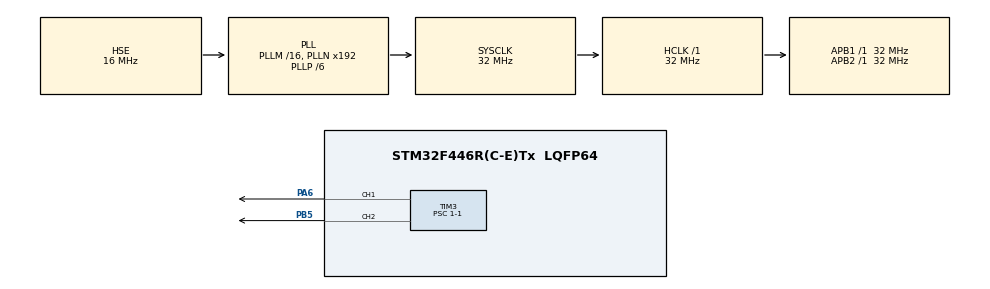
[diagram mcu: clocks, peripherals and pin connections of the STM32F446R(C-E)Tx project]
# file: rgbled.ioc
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Dma.Request0=TIM3_CH2
Dma.Request1=TIM3_CH1/TRIG
Dma.TIM3_CH1/TRIG.1.Direction=DMA_MEMORY_TO_PERIPH
Dma.TIM3_CH1/TRIG.1.FIFOMode=DMA_FIFOMODE_DISABLE
Dma.TIM3_CH1/TRIG.1.Instance=DMA1_Stream4
Dma.TIM3_CH1/TRIG.1.MemDataAlignment=DMA_MDATAALIGN_WORD
Dma.TIM3_CH1/TRIG.1.MemInc=DMA_MINC_ENABLE
Dma.TIM3_CH1/TRIG.1.Mode=DMA_CIRCULAR
Dma.TIM3_CH1/TRIG.1.PeriphDataAlignment=DMA_PDATAALIGN_WORD
Dma.TIM3_CH1/TRIG.1.PeriphInc=DMA_PINC_DISABLE
Dma.TIM3_CH1/TRIG.1.Priority=DMA_PRIORITY_VERY_HIGH
Dma.TIM3_CH2.0.Direction=DMA_MEMORY_TO_PERIPH
Dma.TIM3_CH2.0.FIFOMode=DMA_FIFOMODE_DISABLE
Dma.TIM3_CH2.0.Instance=DMA1_Stream5
Dma.TIM3_CH2.0.MemDataAlignment=DMA_MDATAALIGN_WORD
Dma.TIM3_CH2.0.MemInc=DMA_MINC_ENABLE
Dma.TIM3_CH2.0.Mode=DMA_CIRCULAR
Dma.TIM3_CH2.0.PeriphDataAlignment=DMA_PDATAALIGN_WORD
Dma.TIM3_CH2.0.PeriphInc=DMA_PINC_DISABLE
Dma.TIM3_CH2.0.Priority=DMA_PRIORITY_VERY_HIGH
Mcu.Family=STM32F4
Mcu.Name=STM32F446R(C-E)Tx
Mcu.Package=LQFP64
NVIC.DMA1_Stream4_IRQn=true\:0\:0\:false\:false\:true\:false\:true\:true
NVIC.DMA1_Stream5_IRQn=true\:0\:0\:false\:false\:true\:false\:true\:true
NVIC.PriorityGroup=NVIC_PRIORITYGROUP_4
PA6.Signal=S_TIM3_CH1
PB5.Signal=S_TIM3_CH2
PH0-OSC_IN.Mode=HSE-External-Oscillator
PH0-OSC_IN.Signal=RCC_OSC_IN
PH1-OSC_OUT.Mode=HSE-External-Oscillator
PH1-OSC_OUT.Signal=RCC_OSC_OUT
ProjectManager.HeapSize=0x200
ProjectManager.StackSize=0x400
ProjectManager.TargetToolchain=STM32CubeIDE
RCC.AHBFreq_Value=32000000
RCC.APB1Freq_Value=32000000
RCC.APB1TimFreq_Value=32000000
RCC.APB2Freq_Value=32000000
RCC.APB2TimFreq_Value=32000000
RCC.CortexFreq_Value=32000000
RCC.HCLKFreq_Value=32000000
RCC.HSE_VALUE=16000000
RCC.PLLP=RCC_PLLP_DIV6
RCC.PLLSourceVirtual=RCC_PLLSOURCE_HSE
RCC.SYSCLKFreq_VALUE=32000000
RCC.SYSCLKSource=RCC_SYSCLKSOURCE_PLLCLK
RCC.USBFreq_Value=96000000
RCC.VCOOutputFreq_Value=192000000
SH.S_TIM3_CH1.0=TIM3_CH1,PWM Generation1 CH1
SH.S_TIM3_CH2.0=TIM3_CH2,PWM Generation2 CH2
TIM3.Channel-PWM\ Generation1\ CH1=TIM_CHANNEL_1
TIM3.Channel-PWM\ Generation2\ CH2=TIM_CHANNEL_2
TIM3.OCFastMode_PWM-PWM\ Generation2\ CH2=TIM_OCFAST_ENABLE
TIM3.Period=40-1
TIM3.Prescaler=1-1
VP_TIM3_VS_ClockSourceINT.Mode=Internal
board=custom

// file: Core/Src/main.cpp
/* USER CODE BEGIN Header */
/**
  ******************************************************************************
  * @file           : main.c
  * @brief          : Main program body
  ******************************************************************************
  * @attention
  *
  * Copyright (c) 2024 STMicroelectronics.
  * All rights reserved.
  *
  * This software is licensed under terms that can be found in the LICENSE file
  * in the root directory of this software component.
  * If no LICENSE file comes with this software, it is provided AS-IS.
  *
  ******************************************************************************
  */
/* USER CODE END Header */
#include "main.h"

/* USER CODE BEGIN Includes */
#include "ws2812c.h"
#include "calc.h"

/* USER CODE END Includes */

TIM_HandleTypeDef htim3;
DMA_HandleTypeDef hdma_tim3_ch2;
DMA_HandleTypeDef hdma_tim3_ch1_trig;

/* USER CODE BEGIN PV */
WS2812C NeopixelBoard(&htim3, TIM_CHANNEL_2, &hdma_tim3_ch2);
WS2812C NeopixelTape(&htim3, TIM_CHANNEL_1, &hdma_tim3_ch1_trig);
CALC calc;

uint32_t m = 0;

/* USER CODE END PV */

void SystemClock_Config(void);
static void MX_GPIO_Init(void);
static void MX_DMA_Init(void);
static void MX_TIM3_Init(void);

/* USER CODE BEGIN 0 */
void HAL_TIM_PWM_PulseFinishedCallback(TIM_HandleTypeDef *htim){
	   NeopixelBoard.execute();
	   NeopixelTape.execute();
}

/* USER CODE END 0 */

int main(void)
{

  /* MCU Configuration--------------------------------------------------------*/

  /* Reset of all peripherals, Initializes the Flash interface and the Systick. */
  HAL_Init();

  /* Configure the system clock */
  SystemClock_Config();

  /* Initialize all configured peripherals */
  MX_GPIO_Init();
  MX_DMA_Init();
  MX_TIM3_Init();
  /* USER CODE BEGIN 2 */
  NeopixelBoard.init();
  NeopixelTape.init();

  /* USER CODE END 2 */

  /* Infinite loop */
  while (1)
  {

    /* USER CODE BEGIN 3 */
	  static uint16_t i = 0;
	  i++;
	  if(i >= 360){
		  i -= 360;
	  }
		  for(uint8_t led = 0; led < 32; led++){
			  NeopixelBoard.set_hsv(led, calc.similarityPeak(led, i, 180, i * 2 / 3, 50), 255, calc.range(led, i, 180) * 10);
		  }
		  NeopixelBoard.show();
	  m++;

  }
  /* USER CODE END 3 */
}

void SystemClock_Config(void)
{
  RCC_OscInitTypeDef RCC_OscInitStruct = {0};
  RCC_ClkInitTypeDef RCC_ClkInitStruct = {0};

  /** Configure the main internal regulator output voltage
  */
  __HAL_RCC_PWR_CLK_ENABLE();
  __HAL_PWR_VOLTAGESCALING_CONFIG(PWR_REGULATOR_VOLTAGE_SCALE3);

  /** Initializes the RCC Oscillators according to the specified parameters
  * in the RCC_OscInitTypeDef structure.
  */
  RCC_OscInitStruct.OscillatorType = RCC_OSCILLATORTYPE_HSE;
  RCC_OscInitStruct.HSEState = RCC_HSE_ON;
  RCC_OscInitStruct.PLL.PLLState = RCC_PLL_ON;
  RCC_OscInitStruct.PLL.PLLSource = RCC_PLLSOURCE_HSE;
  RCC_OscInitStruct.PLL.PLLM = 16;
  RCC_OscInitStruct.PLL.PLLN = 192;
  RCC_OscInitStruct.PLL.PLLP = RCC_PLLP_DIV6;
  RCC_OscInitStruct.PLL.PLLQ = 2;
  RCC_OscInitStruct.PLL.PLLR = 2;
  if (HAL_RCC_OscConfig(&RCC_OscInitStruct) != HAL_OK)
  {
    Error_Handler();
  }

  /** Initializes the CPU, AHB and APB buses clocks
  */
  RCC_ClkInitStruct.ClockType = RCC_CLOCKTYPE_HCLK|RCC_CLOCKTYPE_SYSCLK
                              |RCC_CLOCKTYPE_PCLK1|RCC_CLOCKTYPE_PCLK2;
  RCC_ClkInitStruct.SYSCLKSource = RCC_SYSCLKSOURCE_PLLCLK;
  RCC_ClkInitStruct.AHBCLKDivider = RCC_SYSCLK_DIV1;
  RCC_ClkInitStruct.APB1CLKDivider = RCC_HCLK_DIV1;
  RCC_ClkInitStruct.APB2CLKDivider = RCC_HCLK_DIV1;

  if (HAL_RCC_ClockConfig(&RCC_ClkInitStruct, FLASH_LATENCY_1) != HAL_OK)
  {
    Error_Handler();
  }
}

static void MX_TIM3_Init(void)
{

  TIM_ClockConfigTypeDef sClockSourceConfig = {0};
  TIM_MasterConfigTypeDef sMasterConfig = {0};
  TIM_OC_InitTypeDef sConfigOC = {0};

  htim3.Instance = TIM3;
  htim3.Init.Prescaler = 1-1;
  htim3.Init.CounterMode = TIM_COUNTERMODE_UP;
  htim3.Init.Period = 40-1;
  htim3.Init.ClockDivision = TIM_CLOCKDIVISION_DIV1;
  htim3.Init.AutoReloadPreload = TIM_AUTORELOAD_PRELOAD_DISABLE;
  if (HAL_TIM_Base_Init(&htim3) != HAL_OK)
  {
    Error_Handler();
  }
  sClockSourceConfig.ClockSource = TIM_CLOCKSOURCE_INTERNAL;
  if (HAL_TIM_ConfigClockSource(&htim3, &sClockSourceConfig) != HAL_OK)
  {
    Error_Handler();
  }
  if (HAL_TIM_PWM_Init(&htim3) != HAL_OK)
  {
    Error_Handler();
  }
  sMasterConfig.MasterOutputTrigger = TIM_TRGO_RESET;
  sMasterConfig.MasterSlaveMode = TIM_MASTERSLAVEMODE_DISABLE;
  if (HAL_TIMEx_MasterConfigSynchronization(&htim3, &sMasterConfig) != HAL_OK)
  {
    Error_Handler();
  }
  sConfigOC.OCMode = TIM_OCMODE_PWM1;
  sConfigOC.Pulse = 0;
  sConfigOC.OCPolarity = TIM_OCPOLARITY_HIGH;
  sConfigOC.OCFastMode = TIM_OCFAST_DISABLE;
  if (HAL_TIM_PWM_ConfigChannel(&htim3, &sConfigOC, TIM_CHANNEL_1) != HAL_OK)
  {
    Error_Handler();
  }
  sConfigOC.OCFastMode = TIM_OCFAST_ENABLE;
  if (HAL_TIM_PWM_ConfigChannel(&htim3, &sConfigOC, TIM_CHANNEL_2) != HAL_OK)
  {
    Error_Handler();
  }
  HAL_TIM_MspPostInit(&htim3);

}

static void MX_DMA_Init(void)
{

  /* DMA controller clock enable */
  __HAL_RCC_DMA1_CLK_ENABLE();

  /* DMA interrupt init */
  /* DMA1_Stream4_IRQn interrupt configuration */
  HAL_NVIC_SetPriority(DMA1_Stream4_IRQn, 0, 0);
  HAL_NVIC_EnableIRQ(DMA1_Stream4_IRQn);
  /* DMA1_Stream5_IRQn interrupt configuration */
  HAL_NVIC_SetPriority(DMA1_Stream5_IRQn, 0, 0);
  HAL_NVIC_EnableIRQ(DMA1_Stream5_IRQn);

}

static void MX_GPIO_Init(void)
{

  /* GPIO Ports Clock Enable */
  __HAL_RCC_GPIOH_CLK_ENABLE();
  __HAL_RCC_GPIOA_CLK_ENABLE();
  __HAL_RCC_GPIOB_CLK_ENABLE();

}

void Error_Handler(void)
{
  __disable_irq();
  while (1)
  {
  }
}
